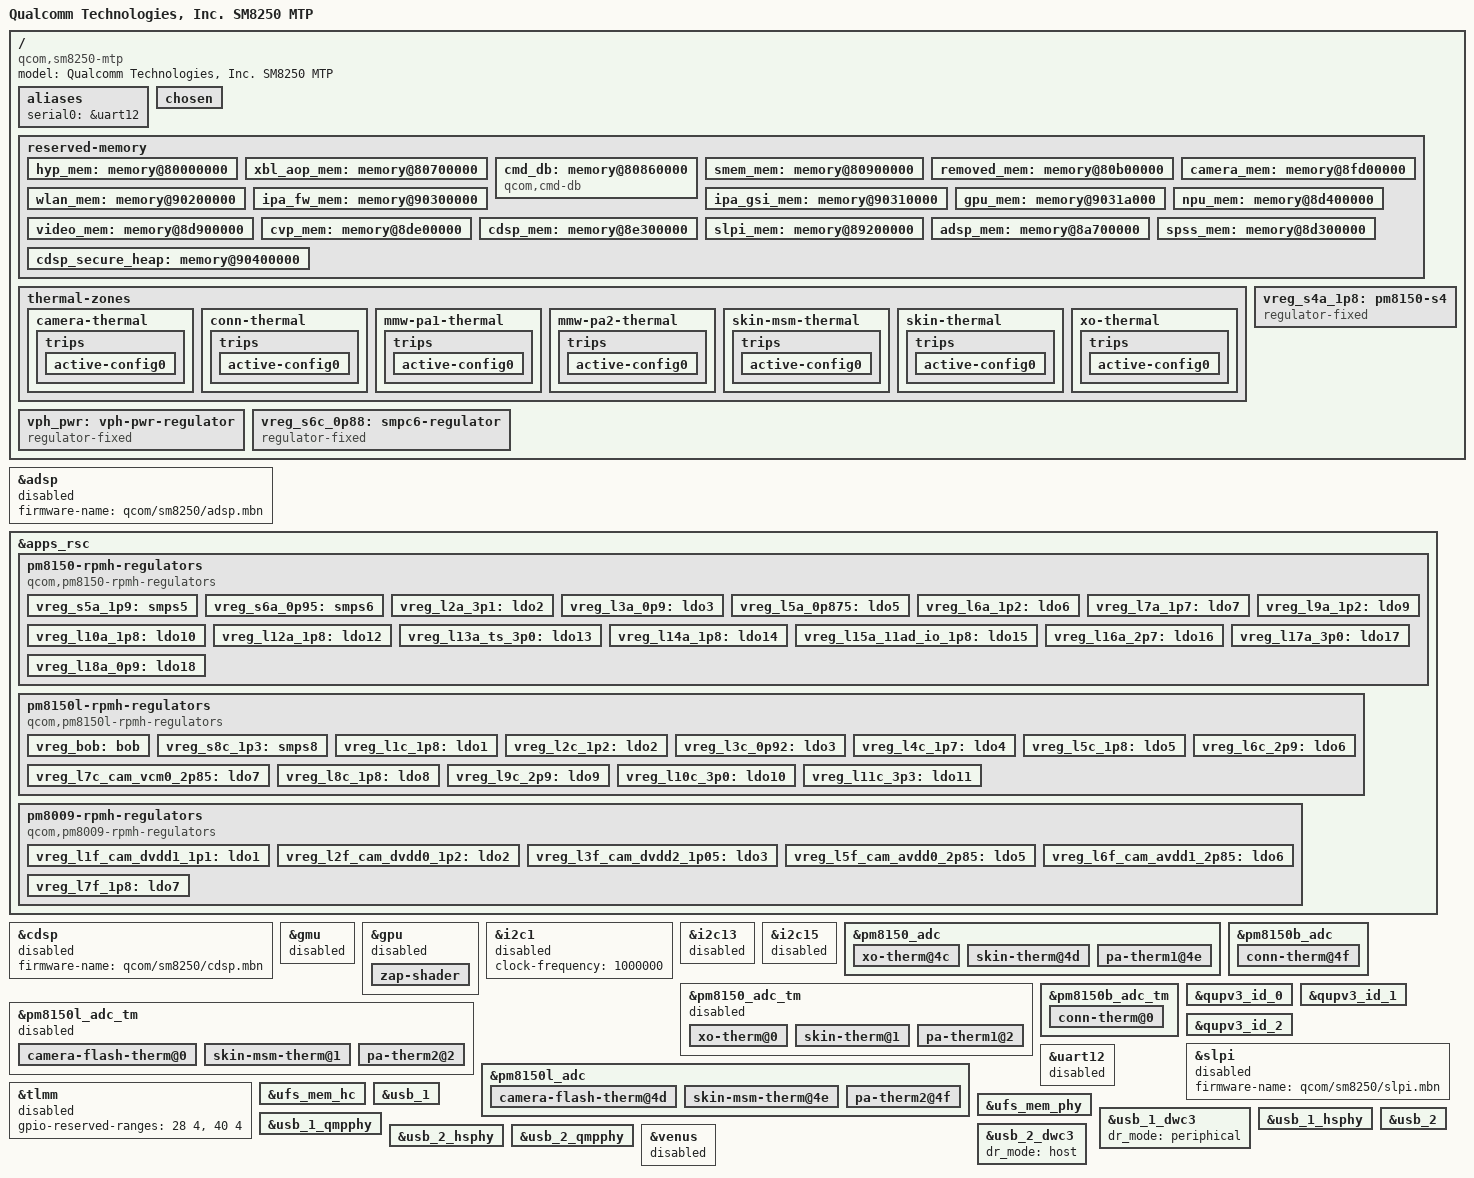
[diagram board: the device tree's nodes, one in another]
// SPDX-License-Identifier: BSD-3-Clause
/*
 * Copyright (c) 2020, The Linux Foundation. All rights reserved.
 */

/dts-v1/;

#include <dt-bindings/regulator/qcom,rpmh-regulator.h>
#include "sm8250.dtsi"
#include "pm8150.dtsi"
#include "pm8150b.dtsi"
#include "pm8150l.dtsi"
#include "pm8009.dtsi"

/delete-node/ &hyp_mem;
/delete-node/ &xbl_aop_mem;
/delete-node/ &cmd_db;
/delete-node/ &smem_mem;
/delete-node/ &removed_mem;
/delete-node/ &camera_mem;
/delete-node/ &wlan_mem;
/delete-node/ &ipa_fw_mem;
/delete-node/ &ipa_gsi_mem;
/delete-node/ &gpu_mem;
/delete-node/ &npu_mem;
/delete-node/ &video_mem;
/delete-node/ &cvp_mem;
/delete-node/ &cdsp_mem;
/delete-node/ &slpi_mem;
/delete-node/ &adsp_mem;
/delete-node/ &spss_mem;
/delete-node/ &cdsp_secure_heap;



/ {
	model = "Qualcomm Technologies, Inc. SM8250 MTP";
	compatible = "qcom,sm8250-mtp", "qcom,sm8250";

	aliases {
		serial0 = &uart12;
	};

	chosen {
	};

reserved-memory {
		#address-cells = <2>;
		#size-cells = <2>;
		ranges;

		hyp_mem: memory@80000000 {
			reg = <0x0 0x80000000 0x0 0x600000>;
			no-map;
		};

		xbl_aop_mem: memory@80700000 {
			reg = <0x0 0x80700000 0x0 0x160000>;
			no-map;
		};

		cmd_db: memory@80860000 {
			compatible = "qcom,cmd-db";
			reg = <0x0 0x80860000 0x0 0x20000>;
			no-map;
		};

		smem_mem: memory@80900000 {
			reg = <0x0 0x80900000 0x0 0x200000>;
			no-map;
		};

		removed_mem: memory@80b00000 {
			reg = <0x0 0x80b00000 0x0 0x6300000>;
			no-map;
		};

		camera_mem: memory@8fd00000 {
			reg = <0x0 0x8fd00000 0x0 0x500000>;
			no-map;
		};

		wlan_mem: memory@90200000 {
			reg = <0x0 0x90200000 0x0 0x100000>;
			no-map;
		};

		ipa_fw_mem: memory@90300000 {
			reg = <0x0 0x90300000 0x0 0x10000>;
			no-map;
		};

		ipa_gsi_mem: memory@90310000 {
			reg = <0x0 0x90310000 0x0 0xa000>;
			no-map;
		};

		gpu_mem: memory@9031a000 {
			reg = <0x0 0x9031a000 0x0 0x2000>;
			no-map;
		};

		npu_mem: memory@8d400000 {
			reg = <0x0 0x8d400000 0x0 0x500000>;
			no-map;
		};

		video_mem: memory@8d900000 {
			reg = <0x0 0x8d900000 0x0 0x500000>;
			no-map;
		};

		cvp_mem: memory@8de00000 {
			reg = <0x0 0x8de00000 0x0 0x500000>;
			no-map;
		};

		cdsp_mem: memory@8e300000 {
			reg = <0x0 0x8e300000 0x0 0x1a00000>;
			no-map;
		};

		slpi_mem: memory@89200000 {
			reg = <0x0 0x89200000 0x0 0x1500000>;
			no-map;
		};

		adsp_mem: memory@8a700000 {
			reg = <0x0 0x8a700000 0x0 0x2c00000>;
			no-map;
		};

		spss_mem: memory@8d300000 {
			reg = <0x0 0x8d300000 0x0 0x100000>;
			no-map;
		};

		cdsp_secure_heap: memory@90400000 {
			reg = <0x0 0x90400000 0x0 0x600000>;
			no-map;
		};
	};

	thermal-zones {
		camera-thermal {
			polling-delay-passive = <0>;
			polling-delay = <0>;
			thermal-sensors = <&pm8150l_adc_tm 0>;

			trips {
				active-config0 {
					temperature = <125000>;
					hysteresis = <1000>;
					type = "passive";
				};
			};
		};

		conn-thermal {
			polling-delay-passive = <0>;
			polling-delay = <0>;
			thermal-sensors = <&pm8150b_adc_tm 0>;

			trips {
				active-config0 {
					temperature = <125000>;
					hysteresis = <1000>;
					type = "passive";
				};
			};
		};

		mmw-pa1-thermal {
			polling-delay-passive = <0>;
			polling-delay = <0>;
			thermal-sensors = <&pm8150_adc_tm 2>;

			trips {
				active-config0 {
					temperature = <125000>;
					hysteresis = <1000>;
					type = "passive";
				};
			};
		};

		mmw-pa2-thermal {
			polling-delay-passive = <0>;
			polling-delay = <0>;
			thermal-sensors = <&pm8150l_adc_tm 2>;

			trips {
				active-config0 {
					temperature = <125000>;
					hysteresis = <1000>;
					type = "passive";
				};
			};
		};

		skin-msm-thermal {
			polling-delay-passive = <0>;
			polling-delay = <0>;
			thermal-sensors = <&pm8150l_adc_tm 1>;

			trips {
				active-config0 {
					temperature = <125000>;
					hysteresis = <1000>;
					type = "passive";
				};
			};
		};

		skin-thermal {
			polling-delay-passive = <0>;
			polling-delay = <0>;
			thermal-sensors = <&pm8150_adc_tm 1>;

			trips {
				active-config0 {
					temperature = <125000>;
					hysteresis = <1000>;
					type = "passive";
				};
			};
		};

		xo-thermal {
			polling-delay-passive = <0>;
			polling-delay = <0>;
			thermal-sensors = <&pm8150_adc_tm 0>;

			trips {
				active-config0 {
					temperature = <125000>;
					hysteresis = <1000>;
					type = "passive";
				};
			};
		};
	};

	vph_pwr: vph-pwr-regulator {
		compatible = "regulator-fixed";
		regulator-name = "vph_pwr";
		regulator-min-microvolt = <3700000>;
		regulator-max-microvolt = <3700000>;
	};

	vreg_s4a_1p8: pm8150-s4 {
		compatible = "regulator-fixed";
		regulator-name = "vreg_s4a_1p8";

		regulator-min-microvolt = <1800000>;
		regulator-max-microvolt = <1800000>;

		regulator-always-on;
		regulator-boot-on;

		vin-supply = <&vph_pwr>;
	};

	vreg_s6c_0p88: smpc6-regulator {
		compatible = "regulator-fixed";
		regulator-name = "vreg_s6c_0p88";

		regulator-min-microvolt = <880000>;
		regulator-max-microvolt = <880000>;
		regulator-always-on;
		vin-supply = <&vph_pwr>;
	};
};

&adsp {
	status = "disabled";
	firmware-name = "qcom/sm8250/adsp.mbn";
};

&apps_rsc {
	pm8150-rpmh-regulators {
		compatible = "qcom,pm8150-rpmh-regulators";
		qcom,pmic-id = "a";

		vdd-s1-supply = <&vph_pwr>;
		vdd-s2-supply = <&vph_pwr>;
		vdd-s3-supply = <&vph_pwr>;
		vdd-s4-supply = <&vph_pwr>;
		vdd-s5-supply = <&vph_pwr>;
		vdd-s6-supply = <&vph_pwr>;
		vdd-s7-supply = <&vph_pwr>;
		vdd-s8-supply = <&vph_pwr>;
		vdd-s9-supply = <&vph_pwr>;
		vdd-s10-supply = <&vph_pwr>;
		vdd-l1-l8-l11-supply = <&vreg_s6c_0p88>;
		vdd-l2-l10-supply = <&vreg_bob>;
		vdd-l3-l4-l5-l18-supply = <&vreg_s6a_0p95>;
		vdd-l6-l9-supply = <&vreg_s8c_1p3>;
		vdd-l7-l12-l14-l15-supply = <&vreg_s5a_1p9>;
		vdd-l13-l16-l17-supply = <&vreg_bob>;

		vreg_s5a_1p9: smps5 {
			regulator-name = "vreg_s5a_1p9";
			regulator-min-microvolt = <1904000>;
			regulator-max-microvolt = <2000000>;
			regulator-initial-mode = <RPMH_REGULATOR_MODE_HPM>;
		};

		vreg_s6a_0p95: smps6 {
			regulator-name = "vreg_s6a_0p95";
			regulator-min-microvolt = <920000>;
			regulator-max-microvolt = <1128000>;
			regulator-initial-mode = <RPMH_REGULATOR_MODE_HPM>;
		};

		vreg_l2a_3p1: ldo2 {
			regulator-name = "vreg_l2a_3p1";
			regulator-min-microvolt = <3072000>;
			regulator-max-microvolt = <3072000>;
			regulator-initial-mode = <RPMH_REGULATOR_MODE_HPM>;
		};

		vreg_l3a_0p9: ldo3 {
			regulator-name = "vreg_l3a_0p9";
			regulator-min-microvolt = <928000>;
			regulator-max-microvolt = <932000>;
			regulator-initial-mode = <RPMH_REGULATOR_MODE_HPM>;
		};

		vreg_l5a_0p875: ldo5 {
			regulator-name = "vreg_l5a_0p875";
			regulator-min-microvolt = <880000>;
			regulator-max-microvolt = <880000>;
			regulator-initial-mode = <RPMH_REGULATOR_MODE_HPM>;
		};

		vreg_l6a_1p2: ldo6 {
			regulator-name = "vreg_l6a_1p2";
			regulator-min-microvolt = <1200000>;
			regulator-max-microvolt = <1200000>;
			regulator-initial-mode = <RPMH_REGULATOR_MODE_HPM>;
		};

		vreg_l7a_1p7: ldo7 {
			regulator-name = "vreg_l7a_1p7";
			regulator-min-microvolt = <1704000>;
			regulator-max-microvolt = <1800000>;
			regulator-initial-mode = <RPMH_REGULATOR_MODE_HPM>;
		};

		vreg_l9a_1p2: ldo9 {
			regulator-name = "vreg_l9a_1p2";
			regulator-min-microvolt = <1200000>;
			regulator-max-microvolt = <1200000>;
			regulator-initial-mode = <RPMH_REGULATOR_MODE_HPM>;
		};

		vreg_l10a_1p8: ldo10 {
			regulator-name = "vreg_l10a_1p8";
			regulator-min-microvolt = <1800000>;
			regulator-max-microvolt = <1800000>;
			regulator-initial-mode = <RPMH_REGULATOR_MODE_HPM>;
		};

		vreg_l12a_1p8: ldo12 {
			regulator-name = "vreg_l12a_1p8";
			regulator-min-microvolt = <1800000>;
			regulator-max-microvolt = <1800000>;
			regulator-initial-mode = <RPMH_REGULATOR_MODE_HPM>;
		};

		vreg_l13a_ts_3p0: ldo13 {
			regulator-name = "vreg_l13a_ts_3p0";
			regulator-min-microvolt = <3008000>;
			regulator-max-microvolt = <3008000>;
			regulator-initial-mode = <RPMH_REGULATOR_MODE_HPM>;
		};

		vreg_l14a_1p8: ldo14 {
			regulator-name = "vreg_l14a_1p8";
			regulator-min-microvolt = <1800000>;
			regulator-max-microvolt = <1880000>;
			regulator-initial-mode = <RPMH_REGULATOR_MODE_HPM>;
		};

		vreg_l15a_11ad_io_1p8: ldo15 {
			regulator-name = "vreg_l15a_11ad_io_1p8";
			regulator-min-microvolt = <1800000>;
			regulator-max-microvolt = <1800000>;
			regulator-initial-mode = <RPMH_REGULATOR_MODE_HPM>;
		};

		vreg_l16a_2p7: ldo16 {
			regulator-name = "vreg_l16a_2p7";
			regulator-min-microvolt = <2704000>;
			regulator-max-microvolt = <2960000>;
			regulator-initial-mode = <RPMH_REGULATOR_MODE_HPM>;
		};

		vreg_l17a_3p0: ldo17 {
			regulator-name = "vreg_l17a_3p0";
			regulator-min-microvolt = <2856000>;
			regulator-max-microvolt = <3008000>;
			regulator-initial-mode = <RPMH_REGULATOR_MODE_HPM>;
		};

		vreg_l18a_0p9: ldo18 {
			regulator-name = "vreg_l18a_0p9";
			regulator-min-microvolt = <912000>;
			regulator-max-microvolt = <912000>;
			regulator-initial-mode = <RPMH_REGULATOR_MODE_HPM>;
		};
	};

	pm8150l-rpmh-regulators {
		compatible = "qcom,pm8150l-rpmh-regulators";
		qcom,pmic-id = "c";

		vdd-s1-supply = <&vph_pwr>;
		vdd-s2-supply = <&vph_pwr>;
		vdd-s3-supply = <&vph_pwr>;
		vdd-s4-supply = <&vph_pwr>;
		vdd-s5-supply = <&vph_pwr>;
		vdd-s6-supply = <&vph_pwr>;
		vdd-s7-supply = <&vph_pwr>;
		vdd-s8-supply = <&vph_pwr>;
		vdd-l1-l8-supply = <&vreg_s4a_1p8>;
		vdd-l2-l3-supply = <&vreg_s8c_1p3>;
		vdd-l4-l5-l6-supply = <&vreg_bob>;
		vdd-l7-l11-supply = <&vreg_bob>;
		vdd-l9-l10-supply = <&vreg_bob>;
		vdd-bob-supply = <&vph_pwr>;

		vreg_bob: bob {
			regulator-name = "vreg_bob";
			regulator-min-microvolt = <3008000>;
			regulator-max-microvolt = <4000000>;
			regulator-initial-mode = <RPMH_REGULATOR_MODE_AUTO>;
		};

		vreg_s8c_1p3: smps8 {
			regulator-name = "vreg_s8c_1p3";
			regulator-min-microvolt = <1352000>;
			regulator-max-microvolt = <1352000>;
			regulator-initial-mode = <RPMH_REGULATOR_MODE_HPM>;
		};

		vreg_l1c_1p8: ldo1 {
			regulator-name = "vreg_l1c_1p8";
			regulator-min-microvolt = <1800000>;
			regulator-max-microvolt = <1800000>;
			regulator-initial-mode = <RPMH_REGULATOR_MODE_HPM>;
		};

		vreg_l2c_1p2: ldo2 {
			regulator-name = "vreg_l2c_1p2";
			regulator-min-microvolt = <1200000>;
			regulator-max-microvolt = <1200000>;
			regulator-initial-mode = <RPMH_REGULATOR_MODE_HPM>;
		};

		vreg_l3c_0p92: ldo3 {
			regulator-name = "vreg_l3c_0p92";
			regulator-min-microvolt = <920000>;
			regulator-max-microvolt = <920000>;
			regulator-initial-mode = <RPMH_REGULATOR_MODE_HPM>;
		};

		vreg_l4c_1p7: ldo4 {
			regulator-name = "vreg_l4c_1p7";
			regulator-min-microvolt = <1704000>;
			regulator-max-microvolt = <2928000>;
			regulator-initial-mode = <RPMH_REGULATOR_MODE_HPM>;
		};

		vreg_l5c_1p8: ldo5 {
			regulator-name = "vreg_l5c_1p8";
			regulator-min-microvolt = <1800000>;
			regulator-max-microvolt = <2928000>;
			regulator-initial-mode = <RPMH_REGULATOR_MODE_HPM>;
		};

		vreg_l6c_2p9: ldo6 {
			regulator-name = "vreg_l6c_2p9";
			regulator-min-microvolt = <1800000>;
			regulator-max-microvolt = <2960000>;
			regulator-initial-mode = <RPMH_REGULATOR_MODE_HPM>;
		};

		vreg_l7c_cam_vcm0_2p85: ldo7 {
			regulator-name = "vreg_l7c_cam_vcm0_2p85";
			regulator-min-microvolt = <2856000>;
			regulator-max-microvolt = <3104000>;
			regulator-initial-mode = <RPMH_REGULATOR_MODE_HPM>;
		};

		vreg_l8c_1p8: ldo8 {
			regulator-name = "vreg_l8c_1p8";
			regulator-min-microvolt = <1800000>;
			regulator-max-microvolt = <1800000>;
			regulator-initial-mode = <RPMH_REGULATOR_MODE_HPM>;
		};

		vreg_l9c_2p9: ldo9 {
			regulator-name = "vreg_l9c_2p9";
			regulator-min-microvolt = <2704000>;
			regulator-max-microvolt = <2960000>;
			regulator-initial-mode = <RPMH_REGULATOR_MODE_HPM>;
		};

		vreg_l10c_3p0: ldo10 {
			regulator-name = "vreg_l10c_3p0";
			regulator-min-microvolt = <3000000>;
			regulator-max-microvolt = <3000000>;
			regulator-initial-mode = <RPMH_REGULATOR_MODE_HPM>;
		};

		vreg_l11c_3p3: ldo11 {
			regulator-name = "vreg_l11c_3p3";
			regulator-min-microvolt = <3000000>;
			regulator-max-microvolt = <3312000>;
			regulator-initial-mode = <RPMH_REGULATOR_MODE_HPM>;
		};
	};

	pm8009-rpmh-regulators {
		compatible = "qcom,pm8009-rpmh-regulators";
		qcom,pmic-id = "f";

		vdd-s1-supply = <&vph_pwr>;
		vdd-s2-supply = <&vreg_bob>;
		vdd-l2-supply = <&vreg_s8c_1p3>;
		vdd-l5-l6-supply = <&vreg_bob>;
		vdd-l7-supply = <&vreg_s4a_1p8>;

		vreg_l1f_cam_dvdd1_1p1: ldo1 {
			regulator-name = "vreg_l1f_cam_dvdd1_1p1";
			regulator-min-microvolt = <1104000>;
			regulator-max-microvolt = <1104000>;
			regulator-initial-mode = <RPMH_REGULATOR_MODE_HPM>;
		};

		vreg_l2f_cam_dvdd0_1p2: ldo2 {
			regulator-name = "vreg_l2f_cam_dvdd0_1p2";
			regulator-min-microvolt = <1200000>;
			regulator-max-microvolt = <1200000>;
			regulator-initial-mode = <RPMH_REGULATOR_MODE_HPM>;
		};

		vreg_l3f_cam_dvdd2_1p05: ldo3 {
			regulator-name = "vreg_l3f_cam_dvdd2_1p05";
			regulator-min-microvolt = <1056000>;
			regulator-max-microvolt = <1056000>;
			regulator-initial-mode = <RPMH_REGULATOR_MODE_HPM>;
		};

		vreg_l5f_cam_avdd0_2p85: ldo5 {
			regulator-name = "vreg_l5f_cam_avdd0_2p85";
			regulator-min-microvolt = <2800000>;
			regulator-max-microvolt = <2800000>;
			regulator-initial-mode = <RPMH_REGULATOR_MODE_HPM>;
		};

		vreg_l6f_cam_avdd1_2p85: ldo6 {
			regulator-name = "vreg_l6f_cam_avdd1_2p85";
			regulator-min-microvolt = <2856000>;
			regulator-max-microvolt = <2856000>;
			regulator-initial-mode = <RPMH_REGULATOR_MODE_HPM>;
		};

		vreg_l7f_1p8: ldo7 {
			regulator-name = "vreg_l7f_1p8";
			regulator-min-microvolt = <1800000>;
			regulator-max-microvolt = <1800000>;
			regulator-initial-mode = <RPMH_REGULATOR_MODE_HPM>;
		};
	};
};

&cdsp {
	status = "disabled";
	firmware-name = "qcom/sm8250/cdsp.mbn";
};

&gmu {
	status = "disabled";
};

&gpu {
	status = "disabled";

	zap-shader {
		memory-region = <&gpu_mem>;
		firmware-name = "qcom/sm8250/a650_zap.mbn";
	};
};

&i2c1 {
	status = "disabled";
	clock-frequency = <1000000>;

	/* NQ NFC chip @28 */
};

&i2c13 {
	status = "disabled";

	/* st,stmfts @ 49 */
};

&i2c15 {
	status = "disabled";

	/* smb1390 @ 10 */
	/* rtc6226 @ 64 */
};

&pm8150_adc {
	xo-therm@4c {
		reg = <ADC5_XO_THERM_100K_PU>;
		qcom,ratiometric;
		qcom,hw-settle-time = <200>;
	};

	skin-therm@4d {
		reg = <ADC5_AMUX_THM1_100K_PU>;
		qcom,ratiometric;
		qcom,hw-settle-time = <200>;
	};

	pa-therm1@4e {
		reg = <ADC5_AMUX_THM2_100K_PU>;
		qcom,ratiometric;
		qcom,hw-settle-time = <200>;
	};
};

&pm8150_adc_tm {
	status = "disabled";

	xo-therm@0 {
		reg = <0>;
		io-channels = <&pm8150_adc ADC5_XO_THERM_100K_PU>;
		qcom,ratiometric;
		qcom,hw-settle-time-us = <200>;
	};

	skin-therm@1 {
		reg = <1>;
		io-channels = <&pm8150_adc ADC5_AMUX_THM1_100K_PU>;
		qcom,ratiometric;
		qcom,hw-settle-time-us = <200>;
	};

	pa-therm1@2 {
		reg = <2>;
		io-channels = <&pm8150_adc ADC5_AMUX_THM2_100K_PU>;
		qcom,ratiometric;
		qcom,hw-settle-time-us = <200>;
	};
};

&pm8150b_adc {
	conn-therm@4f {
		reg = <ADC5_AMUX_THM3_100K_PU>;
		qcom,ratiometric;
		qcom,hw-settle-time = <200>;
	};
};

&pm8150b_adc_tm {
	status = "okay";

	conn-therm@0 {
		reg = <0>;
		io-channels = <&pm8150b_adc ADC5_AMUX_THM3_100K_PU>;
		qcom,ratiometric;
		qcom,hw-settle-time-us = <200>;
	};
};

&pm8150l_adc_tm {
	status = "disabled";

	camera-flash-therm@0 {
		reg = <0>;
		io-channels = <&pm8150l_adc ADC5_AMUX_THM1_100K_PU>;
		qcom,ratiometric;
		qcom,hw-settle-time-us = <200>;
	};

	skin-msm-therm@1 {
		reg = <1>;
		io-channels = <&pm8150l_adc ADC5_AMUX_THM2_100K_PU>;
		qcom,ratiometric;
		qcom,hw-settle-time-us = <200>;
	};

	pa-therm2@2 {
		reg = <2>;
		io-channels = <&pm8150l_adc ADC5_AMUX_THM3_100K_PU>;
		qcom,ratiometric;
		qcom,hw-settle-time-us = <200>;
	};
};

&pm8150l_adc {
	camera-flash-therm@4d {
		reg = <ADC5_AMUX_THM1_100K_PU>;
		qcom,ratiometric;
		qcom,hw-settle-time = <200>;
	};

	skin-msm-therm@4e {
		reg = <ADC5_AMUX_THM2_100K_PU>;
		qcom,ratiometric;
		qcom,hw-settle-time = <200>;
	};

	pa-therm2@4f {
		reg = <ADC5_AMUX_THM3_100K_PU>;
		qcom,ratiometric;
		qcom,hw-settle-time = <200>;
	};
};

&qupv3_id_0 {
	status = "okay";
};

&qupv3_id_1 {
	status = "okay";
};

&qupv3_id_2 {
	status = "okay";
};

&slpi {
	status = "disabled";
	firmware-name = "qcom/sm8250/slpi.mbn";
};

&tlmm {
	status = "disabled";
	gpio-reserved-ranges = <28 4>, <40 4>;
};

&uart12 {
	status = "disabled";
};

&ufs_mem_hc {
	status = "okay";

	vcc-supply = <&vreg_l17a_3p0>;
	vcc-max-microamp = <750000>;
	vccq-supply = <&vreg_l6a_1p2>;
	vccq-max-microamp = <700000>;
	vccq2-supply = <&vreg_s4a_1p8>;
	vccq2-max-microamp = <750000>;
};

&ufs_mem_phy {
	status = "okay";

	vdda-phy-supply = <&vreg_l5a_0p875>;
	vdda-max-microamp = <90200>;
	vdda-pll-supply = <&vreg_l9a_1p2>;
	vdda-pll-max-microamp = <19000>;
};

&usb_1 {
	status = "okay";
};

&usb_1_dwc3 {
	dr_mode = "periphical";
};

&usb_1_hsphy {
	status = "okay";

	vdda-pll-supply = <&vreg_l5a_0p875>;
	vdda18-supply = <&vreg_l12a_1p8>;
	vdda33-supply = <&vreg_l2a_3p1>;
};

&usb_1_qmpphy {
	status = "okay";

	vdda-phy-supply = <&vreg_l9a_1p2>;
	vdda-pll-supply = <&vreg_l18a_0p9>;
};

&usb_2 {
	status = "okay";
};

&usb_2_dwc3 {
	dr_mode = "host";
};

&usb_2_hsphy {
	status = "okay";

	vdda-pll-supply = <&vreg_l5a_0p875>;
	vdda18-supply = <&vreg_l12a_1p8>;
	vdda33-supply = <&vreg_l2a_3p1>;
};

&usb_2_qmpphy {
	status = "okay";

	vdda-phy-supply = <&vreg_l9a_1p2>;
	vdda-pll-supply = <&vreg_l18a_0p9>;
};

&venus {
	status = "disabled";
};
